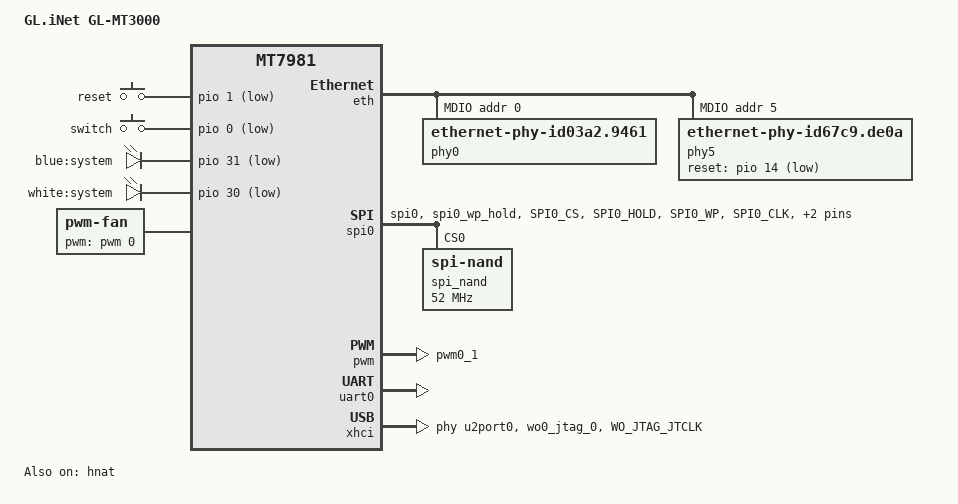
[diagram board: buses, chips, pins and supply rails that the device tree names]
// SPDX-License-Identifier: GPL-2.0-or-later OR MIT
/dts-v1/;

#include "mt7981.dtsi"

/ {
	model = "GL.iNet GL-MT3000";
	compatible = "glinet,mt3000-snand", "mediatek,mt7981";

	aliases {
		led-boot = &led_system_blue;
		led-failsafe = &led_system_blue;
		led-running = &led_system_blue;
		led-upgrade = &led_system_white;
	};

	chosen {
		bootargs = "console=ttyS0,115200n1 loglevel=8 \
			    earlycon=uart8250,mmio32,0x11002000";
	};

	gpio-keys {
		compatible = "gpio-keys";

		reset {
			label = "reset";
			linux,code = <KEY_RESTART>;
			gpios = <&pio 1 GPIO_ACTIVE_LOW>;
		};

		switch {
			label = "switch";
			linux,code = <BTN_0>;
			linux,input-type = <EV_SW>;
			gpios = <&pio 0 GPIO_ACTIVE_LOW>;
		};
	};

	leds {
		compatible = "gpio-leds";

		led_system_blue: system_blue {
			label = "blue:system";
			gpios = <&pio 31 GPIO_ACTIVE_LOW>;
		};

		led_system_white: system_white {
			label = "white:system";
			gpios = <&pio 30 GPIO_ACTIVE_LOW>;
		};
	};

	nmbm_spim_nand {
		compatible = "generic,nmbm";
		#address-cells = <1>;
		#size-cells = <1>;

		lower-mtd-device = <&spi_nand>;
		max-reserved-blocks = <32>;
		forced-create;

		partitions {
			compatible = "fixed-partitions";
			#address-cells = <1>;
			#size-cells = <1>;

			partition@0 {
				label = "BL2";
				reg = <0x0000000 0x0100000>;
				read-only;
			};

			partition@100000 {
				label = "u-boot-env";
				reg = <0x0100000 0x0080000>;
			};

			partition@180000 {
				label = "Factory";
				reg = <0x0180000 0x0200000>;
				read-only;
			};

			partition@380000 {
				label = "FIP";
				reg = <0x0380000 0x0200000>;
				read-only;
			};

			partition@580000 {
				label = "log";
				reg = <0x0580000 0x0040000>;
			};

			partition@5c0000 {
				label = "ubi";
				reg = <0x05c0000 0xf640000>;
			};
		};
	};

	fan: pwm-fan {
		compatible = "pwm-fan";
		cooling-min-state = <0>;
		cooling-max-state = <3>;
		#cooling-cells = <2>;
		pwms = <&pwm 0 40000 0>;
		pinctrl-0 = <&fan_pins>;
		pinctrl-names = "default";
		cooling-levels = <64 128 192 255>;
	};
};

&cpu_thermal {
	trips {
		cpu_trip_critical: critical {
			temperature = <100000>;
			hysteresis = <2000>;
			type = "critical";
		};

		cpu_trip_hot: hot {
			temperature = <55000>;
			hysteresis = <2000>;
			type = "hot";
		};

		cpu_trip_active: active {
			temperature = <40000>;
			hysteresis = <2000>;
			type = "active";
		};

		cpu_trip_passive: passive {
			temperature = <30000>;
			hysteresis = <2000>;
			type = "passive";
		};
	};

	cooling-maps {
		cpu-active-high {
			cooling-device = <&fan 3 3>;
			trip = <&cpu_trip_critical>;
		};

		cpu-active-low {
			cooling-device = <&fan 2 2>;
			trip = <&cpu_trip_hot>;
		};

		cpu-active {
			cooling-device = <&fan 1 1>;
			trip = <&cpu_trip_active>;
		};

		cpu-passive {
			cooling-device = <&fan 0 0>;
			trip = <&cpu_trip_passive>;
		};
	};
};

&eth {
	status = "okay";

	gmac0: mac@0 {
		compatible = "mediatek,eth-mac";
		reg = <0>;
		phy-mode = "2500base-x";

		fixed-link {
			speed = <2500>;
			full-duplex;
			pause;
		};
	};

	gmac1: mac@1 {
		compatible = "mediatek,eth-mac";
		reg = <1>;
		phy-mode = "gmii";
		fixed-link {
			speed = <1000>;
			phy-handle = <&phy0>;
			full-duplex;
			pause;
		};
	};

	mdio: mdio-bus {
		#address-cells = <1>;
		#size-cells = <0>;

		phy0: phy@0 {
			compatible = "ethernet-phy-id03a2.9461";
			reg = <0>;
			nvmem-cells = <&phy_calibration>;
			nvmem-cell-names = "phy-cal-data";
		};

		phy5: phy@5 {
			compatible = "ethernet-phy-id67c9.de0a";
			reg = <5>;
			reset-gpios = <&pio 14 1>;
			reset-assert-us = <600>;
			reset-deassert-us = <20000>;
			phy-mode = "2500base-x";
		};
	};
};

&hnat {
	mtketh-wan = "eth1";
	mtketh-lan = "eth0";
	mtketh-ppd = "eth0";
	mtketh-max-gmac = <2>;
	mtketh-ppe-num = <2>;
	status = "okay";
};

&spi0 {
	pinctrl-names = "default";
	pinctrl-0 = <&spi0_flash_pins>;
	status = "okay";

	spi_nand: spi_nand@0 {
		compatible = "spi-nand";
		#address-cells = <1>;
		#size-cells = <1>;
		reg = <0>;

		spi-max-frequency = <52000000>;
		spi-tx-bus-width = <4>;
		spi-rx-bus-width = <4>;
	};
};

&pio {
	pwm0_pin: pwm0-pin-g0 {
		mux {
			function = "pwm";
			groups = "pwm0_1";
		};
	};

	fan_pins: fan-pins {
		mux {
			function = "wa_aice";
			groups = "wa_aice3";
		};

		power {
			pins = "SPI2_MISO";
			drive-strength = <MTK_DRIVE_8mA>;
			mediatek,pull-up-adv = <1>;
		};
	};

	usb_pwr_pins: usb-pins {
		mux {
			function = "jtag";
			groups = "wo0_jtag_0";
		};

		power {
			pins = "WO_JTAG_JTCLK";
			drive-strength = <MTK_DRIVE_8mA>;
			mediatek,pull-up-adv = <1>;
		};
	};

	spi0_flash_pins: spi0-pins {
		mux {
			function = "spi";
			groups = "spi0", "spi0_wp_hold";
		};

		conf-pu {
			pins = "SPI0_CS", "SPI0_HOLD", "SPI0_WP";
			drive-strength = <MTK_DRIVE_8mA>;
			bias-pull-up = <MTK_PUPD_SET_R1R0_11>;
		};

		conf-pd {
			pins = "SPI0_CLK", "SPI0_MOSI", "SPI0_MISO";
			drive-strength = <MTK_DRIVE_8mA>;
			bias-pull-down = <MTK_PUPD_SET_R1R0_11>;
		};
	};
};

&pwm {
	pinctrl-names = "default";
	pinctrl-0 = <&pwm0_pin>;
	status = "okay";
};

&uart0 {
	status = "okay";
};

&xhci {
	mediatek,u3p-dis-msk = <0x0>;
	phys = <&u2port0 PHY_TYPE_USB2>,
	       <&u3port0 PHY_TYPE_USB3>;
	pinctrl-0 = <&usb_pwr_pins>;
	pinctrl-names = "default";
	status = "okay";
};
